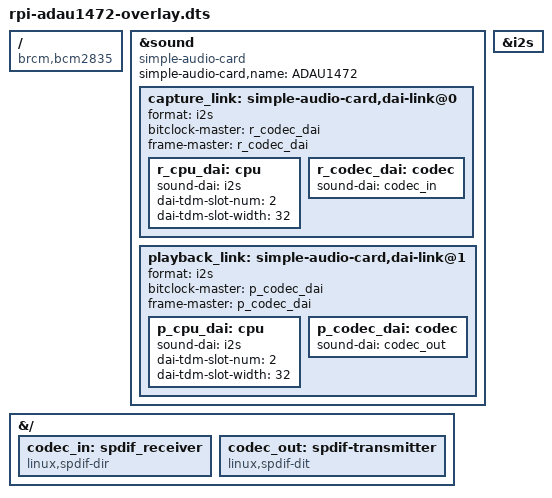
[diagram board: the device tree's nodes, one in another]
// SPDX-License-Identifier: GPL-2.0

/dts-v1/;
/plugin/;

/*
 * Device Tree Overlay for generic I2S audio input and output on RaspberryPi
 * with ADAU1472 master
 */

/ {
	compatible = "brcm,bcm2835", "brcm,bcm2711";
};

&sound {
	compatible = "simple-audio-card";
	simple-audio-card,name = "ADAU1472";

	status="okay";

	capture_link: simple-audio-card,dai-link@0 {
		format = "i2s";

		bitclock-master = <&r_codec_dai>;
		frame-master = <&r_codec_dai>;

		r_cpu_dai: cpu {
			sound-dai = <&i2s>;
			/*
			 * TDM slot configuration
			 * BCLK ratio: 64 x Fs (2 x 32 bit)
			 */
			dai-tdm-slot-num = <2>;
			dai-tdm-slot-width = <32>;
		};

		r_codec_dai: codec {
			sound-dai = <&codec_in>;
		};
	};

	playback_link: simple-audio-card,dai-link@1 {
		format = "i2s";

		bitclock-master = <&p_codec_dai>;
		frame-master = <&p_codec_dai>;

		p_cpu_dai: cpu {
			sound-dai = <&i2s>;
			/*
			 * TDM slot configuration
			 * BCLK ratio: 64 x Fs (2 x 32 bit)
			 */
			dai-tdm-slot-num = <2>;
			dai-tdm-slot-width = <32>;
		};

		p_codec_dai: codec {
			sound-dai = <&codec_out>;
		};
	};
};

&{/} {
	codec_in: spdif_receiver {
		#address-cells = <0>;
		#size-cells = <0>;
		#sound-dai-cells = <0>;
		compatible = "linux,spdif-dir";
		status = "okay";
	};

	codec_out: spdif-transmitter {
		#address-cells = <0>;
		#size-cells = <0>;
		#sound-dai-cells = <0>;
		compatible = "linux,spdif-dit";
		status = "okay";
	};
};

&i2s {
	#sound-dai-cells = <0>;
	status = "okay";
};
